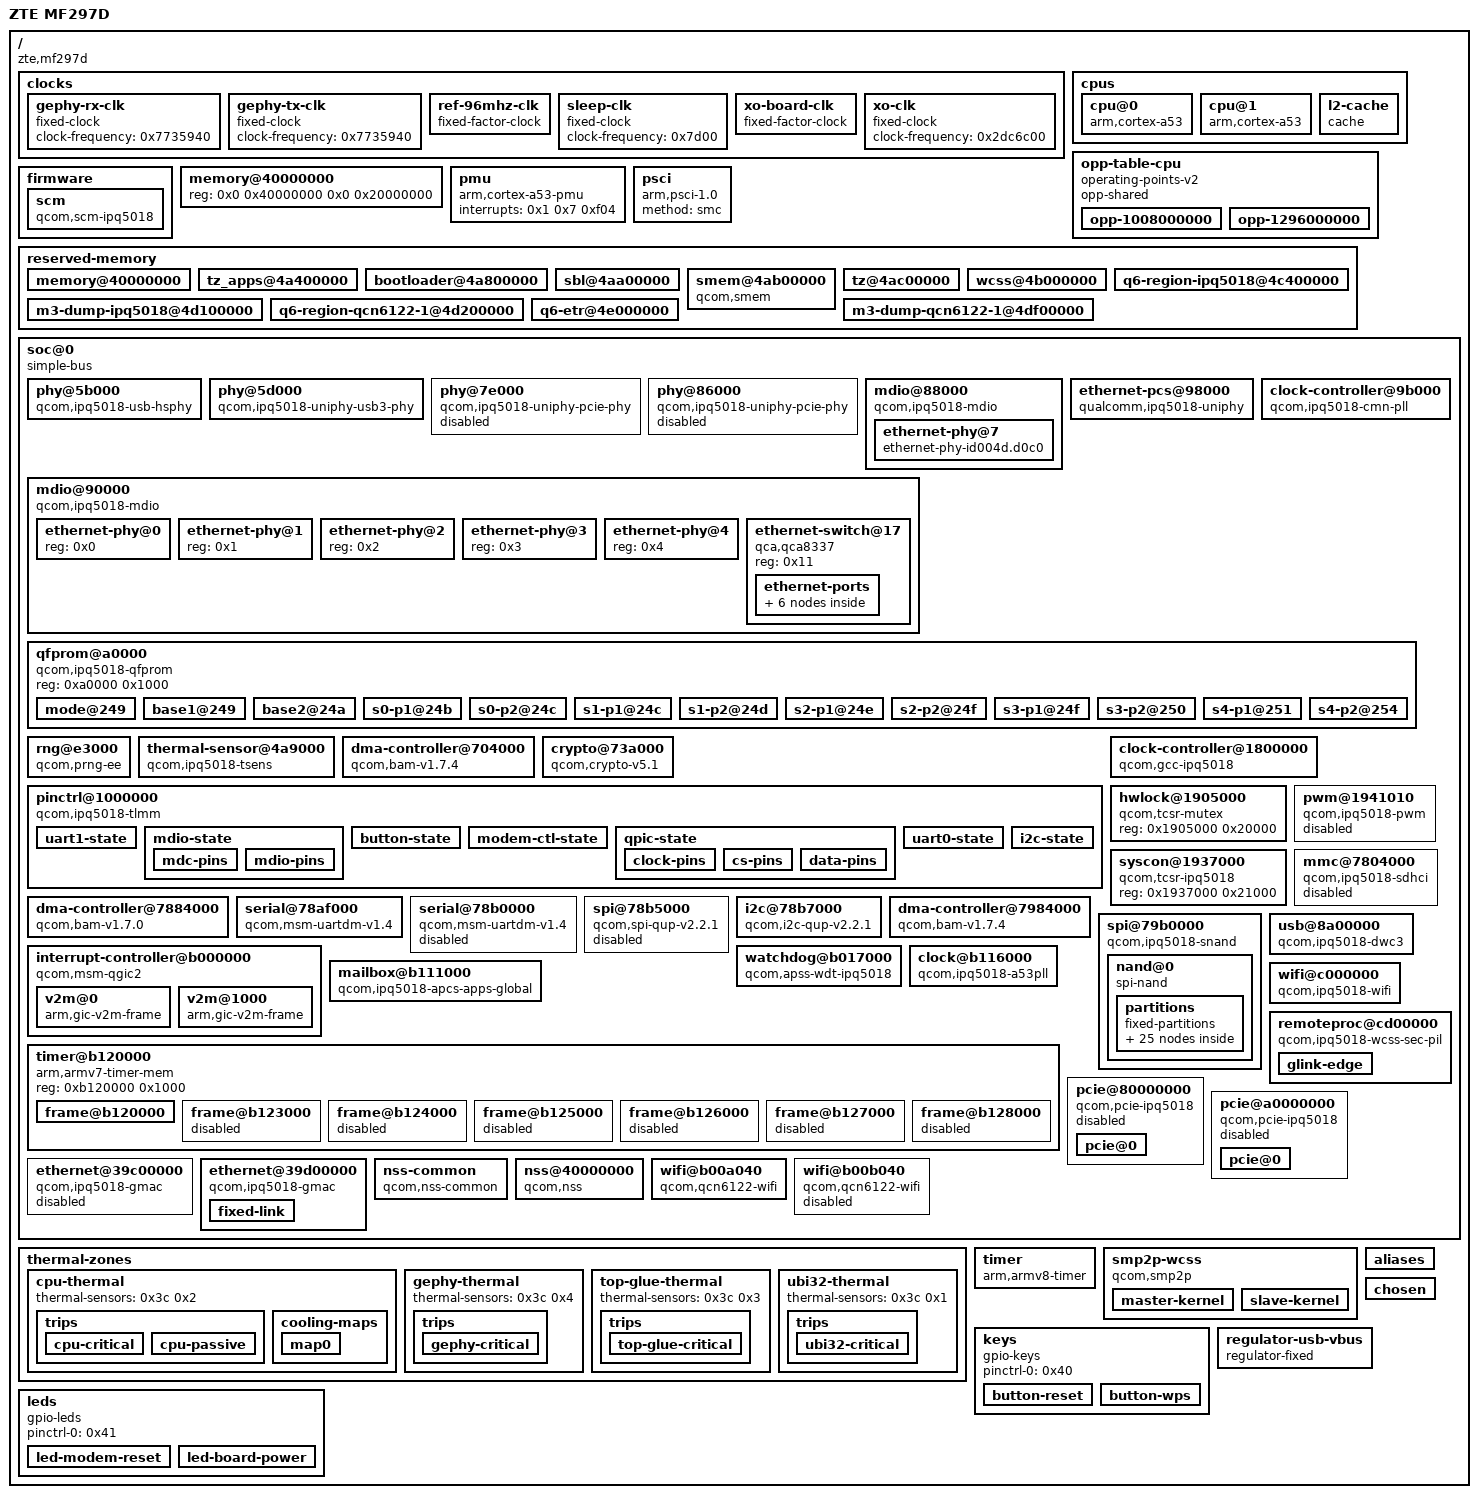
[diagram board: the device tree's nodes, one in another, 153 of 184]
/dts-v1/;

/ {
    interrupt-parent = <0x1>;
    #address-cells = <0x2>;
    #size-cells = <0x2>;
    model = "ZTE MF297D";
    compatible = "zte,mf297d", "qcom,ipq5018";
    clocks {
        gephy-rx-clk {
            compatible = "fixed-clock";
            clock-frequency = <0x7735940>;
            #clock-cells = <0x0>;
            phandle = <0x27>;
        };
        gephy-tx-clk {
            compatible = "fixed-clock";
            clock-frequency = <0x7735940>;
            #clock-cells = <0x0>;
            phandle = <0x28>;
        };
        ref-96mhz-clk {
            compatible = "fixed-factor-clock";
            clocks = <0x2>;
            #clock-cells = <0x0>;
            clock-div = <0x1>;
            clock-mult = <0x2>;
            phandle = <0x3>;
        };
        sleep-clk {
            compatible = "fixed-clock";
            #clock-cells = <0x0>;
            clock-frequency = <0x7d00>;
            phandle = <0x23>;
        };
        xo-board-clk {
            compatible = "fixed-factor-clock";
            clocks = <0x3>;
            #clock-cells = <0x0>;
            clock-div = <0x4>;
            clock-mult = <0x1>;
            phandle = <0x22>;
        };
        xo-clk {
            compatible = "fixed-clock";
            #clock-cells = <0x0>;
            clock-frequency = <0x2dc6c00>;
            phandle = <0x2>;
        };
    };
    cpus {
        #address-cells = <0x1>;
        #size-cells = <0x0>;
        cpu@0 {
            device_type = "cpu";
            compatible = "arm,cortex-a53";
            reg = <0x0>;
            enable-method = "psci";
            next-level-cache = <0x4>;
            clocks = <0x5 0x1>;
            operating-points-v2 = <0x6>;
            #cooling-cells = <0x2>;
            phandle = <0x3e>;
        };
        cpu@1 {
            device_type = "cpu";
            compatible = "arm,cortex-a53";
            reg = <0x1>;
            enable-method = "psci";
            next-level-cache = <0x4>;
            clocks = <0x5 0x1>;
            operating-points-v2 = <0x6>;
            #cooling-cells = <0x2>;
            phandle = <0x3f>;
        };
        l2-cache {
            compatible = "cache";
            cache-level = <0x2>;
            cache-size = <0x80000>;
            cache-unified;
            phandle = <0x4>;
        };
    };
    opp-table-cpu {
        compatible = "operating-points-v2";
        opp-shared;
        phandle = <0x6>;
        opp-1008000000 {
            opp-hz = <0x0 0x3c14dc00>;
            opp-microvolt = <0x10c8e0>;
            clock-latency-ns = <0x30d40>;
        };
        opp-1296000000 {
            opp-hz = <0x0 0x4d3f6400>;
            opp-microvolt = <0x10c8e0>;
            clock-latency-ns = <0x30d40>;
        };
    };
    firmware {
        scm {
            compatible = "qcom,scm-ipq5018", "qcom,scm";
            qcom,dload-mode = <0x7 0x6100>;
            qcom,sdi-enabled;
        };
    };
    memory@40000000 {
        device_type = "memory";
        reg = <0x0 0x40000000 0x0 0x20000000>;
    };
    pmu {
        compatible = "arm,cortex-a53-pmu";
        interrupts = <0x1 0x7 0xf04>;
    };
    psci {
        compatible = "arm,psci-1.0";
        method = "smc";
    };
    reserved-memory {
        #address-cells = <0x2>;
        #size-cells = <0x2>;
        ranges;
        memory@40000000 {
            reg = <0x0 0x40000000 0x0 0x1000000>;
            no-map;
            phandle = <0x39>;
        };
        tz_apps@4a400000 {
            reg = <0x0 0x4a400000 0x0 0x400000>;
            no-map;
        };
        bootloader@4a800000 {
            reg = <0x0 0x4a800000 0x0 0x200000>;
            no-map;
        };
        sbl@4aa00000 {
            reg = <0x0 0x4aa00000 0x0 0x100000>;
            no-map;
        };
        smem@4ab00000 {
            compatible = "qcom,smem";
            reg = <0x0 0x4ab00000 0x0 0x100000>;
            no-map;
            hwlocks = <0x8 0x3>;
        };
        tz@4ac00000 {
            reg = <0x0 0x4ac00000 0x0 0x400000>;
            no-map;
        };
        wcss@4b000000 {
            reg = <0x0 0x4b000000 0x0 0x1400000>;
            no-map;
            phandle = <0x36>;
        };
        q6-region-ipq5018@4c400000 {
            reg = <0x0 0x4c400000 0x0 0xd00000>;
            no-map;
            phandle = <0x33>;
        };
        m3-dump-ipq5018@4d100000 {
            reg = <0x0 0x4d100000 0x0 0x100000>;
            no-map;
            phandle = <0x34>;
        };
        q6-region-qcn6122-1@4d200000 {
            reg = <0x0 0x4d200000 0x0 0xd00000>;
            no-map;
            phandle = <0x3a>;
        };
        m3-dump-qcn6122-1@4df00000 {
            reg = <0x0 0x4df00000 0x0 0x100000>;
            no-map;
            phandle = <0x3b>;
        };
        q6-etr@4e000000 {
            reg = <0x0 0x4e000000 0x0 0x500000>;
            no-map;
        };
    };
    soc@0 {
        compatible = "simple-bus";
        #address-cells = <0x1>;
        #size-cells = <0x1>;
        ranges = <0x0 0x0 0x0 0xffffffff>;
        phy@5b000 {
            compatible = "qcom,ipq5018-usb-hsphy";
            reg = <0x5b000 0x120>;
            clocks = <0x9 0x77>;
            resets = <0x9 0x4f>;
            #phy-cells = <0x0>;
            status = "okay";
            vdd-supply = <0xa>;
            phandle = <0x2f>;
        };
        phy@5d000 {
            compatible = "qcom,ipq5018-uniphy-usb3-phy";
            reg = <0x5d000 0x800>;
            clocks = <0x9 0x77 0x9 0xa9>;
            resets = <0x9 0x63>;
            #clock-cells = <0x0>;
            #phy-cells = <0x0>;
            qcom,phy-usb-mux-sel = <0x7 0x10540>;
            status = "okay";
            vdd-supply = <0xa>;
            phandle = <0x26>;
        };
        phy@7e000 {
            compatible = "qcom,ipq5018-uniphy-pcie-phy";
            reg = <0x7e000 0x800>;
            clocks = <0x9 0x42>;
            resets = <0x9 0x2f 0x9 0x30>;
            #clock-cells = <0x0>;
            #phy-cells = <0x0>;
            num-lanes = <0x1>;
            status = "disabled";
            phandle = <0x25>;
        };
        phy@86000 {
            compatible = "qcom,ipq5018-uniphy-pcie-phy";
            reg = <0x86000 0x1000>;
            clocks = <0x9 0x3c>;
            resets = <0x9 0x23 0x9 0x24>;
            #clock-cells = <0x0>;
            #phy-cells = <0x0>;
            num-lanes = <0x2>;
            status = "disabled";
            phandle = <0x24>;
        };
        mdio@88000 {
            compatible = "qcom,ipq5018-mdio", "qcom,ipq40xx-mdio";
            reg = <0x88000 0x64 0x19475c4 0x4>;
            #address-cells = <0x1>;
            #size-cells = <0x0>;
            clocks = <0x9 0x35>;
            clock-names = "gcc_mdio_ahb_clk";
            status = "okay";
            ethernet-phy@7 {
                compatible = "ethernet-phy-id004d.d0c0";
                reg = <0x7>;
                clocks = <0x9 0x24 0x9 0x25>;
                clock-names = "rx", "tx";
                resets = <0x9 0x6f>;
                phandle = <0x38>;
            };
        };
        mdio@90000 {
            compatible = "qcom,ipq5018-mdio";
            reg = <0x90000 0x64>;
            #address-cells = <0x1>;
            #size-cells = <0x0>;
            clocks = <0x9 0x36>;
            clock-names = "gcc_mdio_ahb_clk";
            status = "okay";
            pinctrl-0 = <0xb>;
            pinctrl-names = "default";
            ethernet-phy@0 {
                reg = <0x0>;
            };
            ethernet-phy@1 {
                reg = <0x1>;
                phandle = <0xc>;
            };
            ethernet-phy@2 {
                reg = <0x2>;
                phandle = <0xd>;
            };
            ethernet-phy@3 {
                reg = <0x3>;
                phandle = <0xe>;
            };
            ethernet-phy@4 {
                reg = <0x4>;
                phandle = <0xf>;
            };
            ethernet-switch@17 {
                compatible = "qca,qca8337";
                reg = <0x11>;
                #address-cells = <0x1>;
                #size-cells = <0x0>;
                ethernet-ports {
                    #address-cells = <0x1>;
                    #size-cells = <0x0>;
                    ethernet-port@2 {
                        reg = <0x2>;
                        label = "lan3";
                        phy-handle = <0xc>;
                    };
                    ethernet-port@3 {
                        reg = <0x3>;
                        label = "lan2";
                        phy-handle = <0xd>;
                    };
                    ethernet-port@4 {
                        reg = <0x4>;
                        label = "lan1";
                        phy-handle = <0xe>;
                    };
                    ethernet-port@5 {
                        reg = <0x5>;
                        label = "lan4";
                        phy-handle = <0xf>;
                    };
                    ethernet-port@6 {
                        reg = <0x6>;
                        label = "cpu";
                        phy-mode = "sgmii";
                        ethernet = <0x10>;
                        qca,sgmii-enable-pll;
                        fixed-link {
                            speed = <0x3e8>;
                            full-duplex;
                        };
                    };
                };
            };
        };
        ethernet-pcs@98000 {
            compatible = "qualcomm,ipq5018-uniphy";
            reg = <0x98000 0x800>;
            #clock-cells = <0x1>;
            clocks = <0x9 0x6e 0x9 0x70 0x9 0x6f 0x9 0x71 0x11 0x3>;
            clock-names = "ahb", "sys", "port5_rx", "port5_tx", "ref";
            clock-output-names = "uniphy0_gcc_rx_clk", "uniphy0_gcc_tx_clk", "uniphy0_ref_clk";
            resets = <0x9 0x6e>;
            reset-names = "soft";
            #pcs-cells = <0x0>;
            status = "okay";
            assigned-clocks = <0x12 0x2>;
            assigned-clock-rates = <0x17d7840>;
            phandle = <0x12>;
        };
        clock-controller@9b000 {
            compatible = "qcom,ipq5018-cmn-pll";
            reg = <0x9b000 0x800>;
            clocks = <0x3 0x9 0x1d 0x9 0x1e>;
            clock-names = "ref", "ahb", "sys";
            #clock-cells = <0x1>;
            assigned-clocks = <0x11 0x0>;
            assigned-clock-rates-u64 = <0x1 0x1e1a3000>;
            phandle = <0x11>;
        };
        qfprom@a0000 {
            compatible = "qcom,ipq5018-qfprom", "qcom,qfprom";
            reg = <0xa0000 0x1000>;
            #address-cells = <0x1>;
            #size-cells = <0x1>;
            status = "okay";
            mode@249 {
                reg = <0x249 0x1>;
                bits = <0x0 0x3>;
                phandle = <0x13>;
            };
            base1@249 {
                reg = <0x249 0x2>;
                bits = <0x3 0x8>;
                phandle = <0x14>;
            };
            base2@24a {
                reg = <0x24a 0x2>;
                bits = <0x3 0x8>;
                phandle = <0x15>;
            };
            s0-p1@24b {
                reg = <0x24b 0x2>;
                bits = <0x2 0x6>;
                phandle = <0x16>;
            };
            s0-p2@24c {
                reg = <0x24c 0x1>;
                bits = <0x1 0x6>;
                phandle = <0x17>;
            };
            s1-p1@24c {
                reg = <0x24c 0x2>;
                bits = <0x7 0x6>;
                phandle = <0x18>;
            };
            s1-p2@24d {
                reg = <0x24d 0x2>;
                bits = <0x5 0x6>;
                phandle = <0x19>;
            };
            s2-p1@24e {
                reg = <0x24e 0x2>;
                bits = <0x3 0x6>;
                phandle = <0x1a>;
            };
            s2-p2@24f {
                reg = <0x24f 0x1>;
                bits = <0x1 0x6>;
                phandle = <0x1b>;
            };
            s3-p1@24f {
                reg = <0x24f 0x2>;
                bits = <0x7 0x6>;
                phandle = <0x1c>;
            };
            s3-p2@250 {
                reg = <0x250 0x2>;
                bits = <0x5 0x6>;
                phandle = <0x1d>;
            };
            s4-p1@251 {
                reg = <0x251 0x2>;
                bits = <0x3 0x6>;
                phandle = <0x1e>;
            };
            s4-p2@254 {
                reg = <0x254 0x1>;
                bits = <0x0 0x6>;
                phandle = <0x1f>;
            };
        };
        rng@e3000 {
            compatible = "qcom,prng-ee";
            reg = <0xe3000 0x1000>;
            clocks = <0x9 0x43>;
            clock-names = "core";
            status = "okay";
        };
        thermal-sensor@4a9000 {
            compatible = "qcom,ipq5018-tsens";
            reg = <0x4a9000 0x1000 0x4a8000 0x1000>;
            nvmem-cells = <0x13 0x14 0x15 0x16 0x17 0x18 0x19 0x1a 0x1b 0x1c 0x1d 0x1e 0x1f>;
            nvmem-cell-names = "mode", "base1", "base2", "s0_p1", "s0_p2", "s1_p1", "s1_p2", "s2_p1", "s2_p2", "s3_p1", "s3_p2", "s4_p1", "s4_p2";
            interrupts = <0x0 0xb8 0x1>;
            interrupt-names = "uplow";
            #qcom,sensors = <0x5>;
            #thermal-sensor-cells = <0x1>;
            phandle = <0x3c>;
        };
        dma-controller@704000 {
            compatible = "qcom,bam-v1.7.4", "qcom,bam-v1.7.0";
            reg = <0x704000 0x20000>;
            interrupts = <0x0 0xcf 0x4>;
            clocks = <0x9 0x1f>;
            clock-names = "bam_clk";
            #dma-cells = <0x1>;
            qcom,ee = <0x1>;
            qcom,controlled-remotely;
            status = "okay";
            phandle = <0x20>;
        };
        crypto@73a000 {
            compatible = "qcom,crypto-v5.1";
            reg = <0x73a000 0x6000>;
            clocks = <0x9 0x1f 0x9 0x20 0x9 0x21>;
            clock-names = "iface", "bus", "core";
            dmas = <0x20 0x2 0x20 0x3>;
            dma-names = "rx", "tx";
            status = "okay";
        };
        pinctrl@1000000 {
            compatible = "qcom,ipq5018-tlmm";
            reg = <0x1000000 0x300000>;
            interrupts = <0x0 0xd0 0x4>;
            gpio-controller;
            #gpio-cells = <0x2>;
            gpio-ranges = <0x21 0x0 0x0 0x2f>;
            interrupt-controller;
            #interrupt-cells = <0x2>;
            phandle = <0x21>;
            uart1-state {
                pins = "gpio31", "gpio32", "gpio33", "gpio34";
                function = "blsp1_uart1";
                drive-strength = <0x8>;
                bias-pull-down;
            };
            mdio-state {
                phandle = <0xb>;
                mdc-pins {
                    pins = "gpio36";
                    function = "mdc";
                    drive-strength = <0x8>;
                    bias-pull-up;
                };
                mdio-pins {
                    pins = "gpio37";
                    function = "mdio";
                    drive-strength = <0x8>;
                    bias-pull-up;
                };
            };
            button-state {
                pins = "gpio32", "gpio38";
                function = "gpio";
                drive-strength = <0x8>;
                bias-pull-up;
                phandle = <0x40>;
            };
            modem-ctl-state {
                pins = "gpio26", "gpio35";
                function = "gpio";
                drive-strength = <0x8>;
                bias-disable;
                phandle = <0x41>;
            };
            qpic-state {
                phandle = <0x2d>;
                clock-pins {
                    pins = "gpio9";
                    function = "qspi_clk";
                    drive-strength = <0x8>;
                    bias-disable;
                };
                cs-pins {
                    pins = "gpio8";
                    function = "qspi_cs";
                    drive-strength = <0x8>;
                    bias-disable;
                };
                data-pins {
                    pins = "gpio4", "gpio5", "gpio6", "gpio7";
                    function = "qspi_data";
                    drive-strength = <0x8>;
                    bias-disable;
                };
            };
            uart0-state {
                pins = "gpio20", "gpio21";
                function = "blsp0_uart0";
                drive-strength = <0x8>;
                bias-disable;
                phandle = <0x29>;
            };
            i2c-state {
                pins = "gpio33", "gpio34";
                function = "blsp2_i2c0";
                drive-strength = <0x8>;
                bias-disable;
                phandle = <0x2b>;
            };
        };
        clock-controller@1800000 {
            compatible = "qcom,gcc-ipq5018";
            reg = <0x1800000 0x80000>;
            clocks = <0x22 0x23 0x24 0x25 0x26 0x27 0x28 0x12 0x0 0x12 0x1>;
            #clock-cells = <0x1>;
            #reset-cells = <0x1>;
            phandle = <0x9>;
        };
        hwlock@1905000 {
            compatible = "qcom,tcsr-mutex";
            reg = <0x1905000 0x20000>;
            #hwlock-cells = <0x1>;
            phandle = <0x8>;
        };
        syscon@1937000 {
            compatible = "qcom,tcsr-ipq5018", "syscon";
            reg = <0x1937000 0x21000>;
            phandle = <0x7>;
        };
        pwm@1941010 {
            compatible = "qcom,ipq5018-pwm", "qcom,ipq6018-pwm";
            reg = <0x1941010 0x20>;
            clocks = <0x9 0x12>;
            assigned-clocks = <0x9 0x12>;
            assigned-clock-rates = <0x5f5e100>;
            #pwm-cells = <0x3>;
            status = "disabled";
        };
        mmc@7804000 {
            compatible = "qcom,ipq5018-sdhci", "qcom,sdhci-msm-v5";
            reg = <0x7804000 0x1000>;
            reg-names = "hc";
            interrupts = <0x0 0x7b 0x4 0x0 0x8a 0x4>;
            interrupt-names = "hc_irq", "pwr_irq";
            clocks = <0x9 0x59 0x9 0x5a 0x22>;
            clock-names = "iface", "core", "xo";
            non-removable;
            status = "disabled";
        };
        dma-controller@7884000 {
            compatible = "qcom,bam-v1.7.0";
            reg = <0x7884000 0x1d000>;
            interrupts = <0x0 0xee 0x4>;
            clocks = <0x9 0x13>;
            clock-names = "bam_clk";
            #dma-cells = <0x1>;
            qcom,ee = <0x0>;
            phandle = <0x2a>;
        };
        serial@78af000 {
            compatible = "qcom,msm-uartdm-v1.4", "qcom,msm-uartdm";
            reg = <0x78af000 0x200>;
            interrupts = <0x0 0x6b 0x4>;
            clocks = <0x9 0x1a 0x9 0x13>;
            clock-names = "core", "iface";
            status = "okay";
            pinctrl-0 = <0x29>;
            pinctrl-names = "default";
        };
        serial@78b0000 {
            compatible = "qcom,msm-uartdm-v1.4", "qcom,msm-uartdm";
            reg = <0x78b0000 0x200>;
            interrupts = <0x0 0x6c 0x4>;
            clocks = <0x9 0x1b 0x9 0x13>;
            clock-names = "core", "iface";
            status = "disabled";
        };
        spi@78b5000 {
            compatible = "qcom,spi-qup-v2.2.1";
            #address-cells = <0x1>;
            #size-cells = <0x0>;
            reg = <0x78b5000 0x600>;
            interrupts = <0x0 0x5f 0x4>;
            clocks = <0x9 0x15 0x9 0x13>;
            clock-names = "core", "iface";
            dmas = <0x2a 0x4 0x2a 0x5>;
            dma-names = "tx", "rx";
            status = "disabled";
        };
        i2c@78b7000 {
            compatible = "qcom,i2c-qup-v2.2.1";
            reg = <0x78b7000 0x600>;
            #address-cells = <0x1>;
            #size-cells = <0x0>;
            interrupts = <0x0 0x61 0x4>;
            clocks = <0x9 0x18 0x9 0x13>;
            clock-names = "core", "iface";
            clock-frequency = <0x61a80>;
            dmas = <0x2a 0x9 0x2a 0x8>;
            dma-names = "tx", "rx";
            status = "okay";
            pinctrl-0 = <0x2b>;
            pinctrl-names = "default";
        };
        dma-controller@7984000 {
            compatible = "qcom,bam-v1.7.4", "qcom,bam-v1.7.0";
            reg = <0x7984000 0x1c000>;
            interrupts = <0x0 0x92 0x4>;
            clocks = <0x9 0x56>;
            clock-names = "bam_clk";
            #dma-cells = <0x1>;
            qcom,ee = <0x0>;
            status = "okay";
            phandle = <0x2c>;
        };
        spi@79b0000 {
            compatible = "qcom,ipq5018-snand", "qcom,ipq9574-snand";
            reg = <0x79b0000 0x10000>;
            #address-cells = <0x1>;
            #size-cells = <0x0>;
            clocks = <0x9 0x57 0x9 0x56 0x9 0x58>;
            clock-names = "core", "aon", "iom";
            dmas = <0x2c 0x0 0x2c 0x1 0x2c 0x2>;
            dma-names = "tx", "rx", "cmd";
            status = "okay";
            pinctrl-0 = <0x2d>;
            pinctrl-names = "default";
            phandle = <0x2e>;
            nand@0 {
                compatible = "spi-nand";
                reg = <0x0>;
                nand-ecc-engine = <0x2e>;
                nand-ecc-strength = <0x4>;
                nand-ecc-step-size = <0x200>;
                nand-bus-width = <0x8>;
                partitions {
                    compatible = "fixed-partitions";
                    #address-cells = <0x1>;
                    #size-cells = <0x1>;
                    partition@0 {
                        label = "0:sbl1";
                        reg = <0x0 0x80000>;
                        read-only;
                    };
                    partition@80000 {
                        label = "0:mibib";
                        reg = <0x80000 0x80000>;
                        read-only;
                    };
                    partition@100000 {
                        label = "0:bootconfig";
                        reg = <0x100000 0x40000>;
                        read-only;
                    };
                    partition@140000 {
                        label = "0:bootconfig1";
                        reg = <0x140000 0x40000>;
                        read-only;
                    };
                    partition@180000 {
                        label = "0:qsee";
                        reg = <0x180000 0x100000>;
                        read-only;
                    };
                    partition@280000 {
                        label = "0:qsee_1";
                        reg = <0x280000 0x100000>;
                        read-only;
                    };
                    partition@380000 {
                        label = "0:devcfg";
                        reg = <0x380000 0x40000>;
                        read-only;
                    };
                    partition@3c0000 {
                        label = "0:devcfg_1";
                        reg = <0x3c0000 0x40000>;
                        read-only;
                    };
                    partition@400000 {
                        label = "0:cdt";
                        reg = <0x400000 0x40000>;
                        read-only;
                    };
                    partition@440000 {
                        label = "0:cdt_1";
                        reg = <0x440000 0x40000>;
                        read-only;
                    };
                    partition@480000 {
                        label = "0:appsblenv";
                        reg = <0x480000 0x80000>;
                    };
                    partition@500000 {
                        label = "0:appsbl";
                        reg = <0x500000 0x140000>;
                        read-only;
                    };
                    partition@640000 {
                        label = "0:appsbl_1";
                        reg = <0x640000 0x140000>;
                        read-only;
                    };
                    partition@780000 {
                        label = "0:art";
                        reg = <0x780000 0x100000>;
                        read-only;
                    };
                    partition@880000 {
                        label = "0:training";
                        reg = <0x880000 0x80000>;
                        read-only;
                    };
                    partition@900000 {
                        label = "fota-flag";
                        reg = <0x900000 0xa0000>;
                        read-only;
                    };
                    partition@9a0000 {
                        label = "mac";
                        reg = <0x9a0000 0x80000>;
                        read-only;
                        nvmem-layout {
                            compatible = "fixed-layout";
                            #address-cells = <0x1>;
                            #size-cells = <0x1>;
                            macaddr@0 {
                                compatible = "mac-base";
                                reg = <0x0 0x6>;
                                #nvmem-cell-cells = <0x1>;
                            };
                        };
                    };
                    partition@a20000 {
                        label = "cfg-param";
                        reg = <0xa20000 0x1400000>;
                        read-only;
                    };
                    partition@1e20000 {
                        label = "log";
                        reg = <0x1e20000 0x600000>;
                        read-only;
                    };
                    partition@2420000 {
                        label = "oops";
                        reg = <0x2420000 0xa0000>;
                    };
                    partition@24c0000 {
                        label = "web";
                        reg = <0x24c0000 0x800000>;
                        read-only;
                    };
                    partition@2cc0000 {
                        label = "rootfs";
                        reg = <0x2cc0000 0x3a00000>;
                    };
                    partition@66c0000 {
                        label = "ubi_data";
                        reg = <0x66c0000 0x9940000>;
                    };
                };
            };
        };
        usb@8a00000 {
            compatible = "qcom,ipq5018-dwc3", "qcom,snps-dwc3";
            reg = <0x8a00000 0xfc100>;
            clocks = <0x9 0x75 0x9 0x66 0x9 0x78 0x9 0x76 0x9 0x72 0x9 0x74>;
            clock-names = "core", "iface", "sleep", "mock_utmi", "aux", "lfps";
            assigned-clocks = <0x9 0x76>;
            assigned-clock-rates = <0x3938700>;
            interrupts = <0x0 0x8c 0x4 0x0 0x86 0x4 0x0 0x79 0x4 0x0 0x78 0x4>;
            interrupt-names = "dwc_usb3", "pwr_event", "dp_hs_phy_irq", "dm_hs_phy_irq";
            resets = <0x9 0x62>;
            phys = <0x2f 0x26>;
            phy-names = "usb2-phy", "usb3-phy";
            tx-fifo-resize;
            snps,is-utmi-l1-suspend;
            snps,hird-threshold = [00];
            snps,dis_u2_susphy_quirk;
            snps,dis_u3_susphy_quirk;
            status = "okay";
            dr_mode = "host";
        };
        interrupt-controller@b000000 {
            compatible = "qcom,msm-qgic2";
            reg = <0xb000000 0x1000 0xb002000 0x2000 0xb001000 0x1000 0xb004000 0x2000>;
            interrupts = <0x1 0x9 0xf04>;
            interrupt-controller;
            #interrupt-cells = <0x3>;
            #address-cells = <0x1>;
            #size-cells = <0x1>;
            ranges = <0x0 0xb00a000 0x1ffa>;
            phandle = <0x1>;
            v2m@0 {
                compatible = "arm,gic-v2m-frame";
                reg = <0x0 0xff8>;
                msi-controller;
                phandle = <0x37>;
            };
            v2m@1000 {
                compatible = "arm,gic-v2m-frame";
                reg = <0x1000 0xff8>;
                msi-controller;
            };
        };
        watchdog@b017000 {
            compatible = "qcom,apss-wdt-ipq5018", "qcom,kpss-wdt";
            reg = <0xb017000 0x40>;
            interrupts = <0x0 0x3 0x1>;
            clocks = <0x23>;
        };
        mailbox@b111000 {
            compatible = "qcom,ipq5018-apcs-apps-global", "qcom,ipq6018-apcs-apps-global";
            reg = <0xb111000 0x1000>;
            #clock-cells = <0x1>;
            clocks = <0x30 0x22 0x9 0x1>;
            clock-names = "pll", "xo", "gpll0";
            #mbox-cells = <0x1>;
            phandle = <0x5>;
        };
        clock@b116000 {
            compatible = "qcom,ipq5018-a53pll";
            reg = <0xb116000 0x40>;
            #clock-cells = <0x0>;
            clocks = <0x22>;
            clock-names = "xo";
            phandle = <0x30>;
        };
        timer@b120000 {
            compatible = "arm,armv7-timer-mem";
            reg = <0xb120000 0x1000>;
            #address-cells = <0x1>;
            #size-cells = <0x1>;
            ranges;
            frame@b120000 {
                reg = <0xb121000 0x1000 0xb122000 0x1000>;
                interrupts = <0x0 0x8 0x4 0x0 0x7 0x4>;
                frame-number = <0x0>;
            };
            frame@b123000 {
                reg = <0xb123000 0x1000>;
                interrupts = <0x0 0x9 0x4>;
                frame-number = <0x1>;
                status = "disabled";
            };
            frame@b124000 {
                frame-number = <0x2>;
                interrupts = <0x0 0xa 0x4>;
                reg = <0xb124000 0x1000>;
                status = "disabled";
            };
            frame@b125000 {
                reg = <0xb125000 0x1000>;
                interrupts = <0x0 0xb 0x4>;
                frame-number = <0x3>;
                status = "disabled";
            };
            frame@b126000 {
                reg = <0xb126000 0x1000>;
                interrupts = <0x0 0xc 0x4>;
                frame-number = <0x4>;
                status = "disabled";
            };
            frame@b127000 {
                reg = <0xb127000 0x1000>;
                interrupts = <0x0 0xd 0x4>;
                frame-number = <0x5>;
                status = "disabled";
            };
            frame@b128000 {
                reg = <0xb128000 0x1000>;
                interrupts = <0x0 0xe 0x4>;
                frame-number = <0x6>;
                status = "disabled";
            };
        };
        wifi@c000000 {
            compatible = "qcom,ipq5018-wifi";
            reg = <0xc000000 0x1000000>;
            interrupt-names = "misc-pulse1", "misc-latch", "sw-exception", "watchdog", "ce0", "ce1", "ce2", "ce3", "ce4", "ce5", "ce6", "ce7", "ce8", "ce9", "ce10", "ce11", "host2wbm-desc-feed", "host2reo-re-injection", "host2reo-command", "host2rxdma-monitor-ring3", "host2rxdma-monitor-ring2", "host2rxdma-monitor-ring1", "reo2ost-exception", "wbm2host-rx-release", "reo2host-status", "reo2host-destination-ring4", "reo2host-destination-ring3", "reo2host-destination-ring2", "reo2host-destination-ring1", "rxdma2host-monitor-destination-mac3", "rxdma2host-monitor-destination-mac2", "rxdma2host-monitor-destination-mac1", "ppdu-end-interrupts-mac3", "ppdu-end-interrupts-mac2", "ppdu-end-interrupts-mac1", "rxdma2host-monitor-status-ring-mac3", "rxdma2host-monitor-status-ring-mac2", "rxdma2host-monitor-status-ring-mac1", "host2rxdma-host-buf-ring-mac3", "host2rxdma-host-buf-ring-mac2", "host2rxdma-host-buf-ring-mac1", "rxdma2host-destination-ring-mac3", "rxdma2host-destination-ring-mac2", "rxdma2host-destination-ring-mac1", "host2tcl-input-ring4", "host2tcl-input-ring3", "host2tcl-input-ring2", "host2tcl-input-ring1", "wbm2host-tx-completions-ring3", "wbm2host-tx-completions-ring2", "wbm2host-tx-completions-ring1", "tcl2host-status-ring", "fatal", "ready", "spawn", "stop-ack";
            status = "okay";
            nss-radio-priority = <0x0>;
            interrupts-extended = <0x1 0x0 0x120 0x1 0x1 0x0 0x121 0x1 0x1 0x0 0x122 0x1 0x1 0x0 0x123 0x1 0x1 0x0 0x124 0x1 0x1 0x0 0x125 0x1 0x1 0x0 0x126 0x1 0x1 0x0 0x127 0x1 0x1 0x0 0x128 0x1 0x1 0x0 0x129 0x1 0x1 0x0 0x12a 0x1 0x1 0x0 0x12b 0x1 0x1 0x0 0x12c 0x1 0x1 0x0 0x12d 0x1 0x1 0x0 0x12e 0x1 0x1 0x0 0x12f 0x1 0x1 0x0 0x130 0x1 0x1 0x0 0x131 0x1 0x1 0x0 0x132 0x1 0x1 0x0 0x133 0x1 0x1 0x0 0x134 0x1 0x1 0x0 0x135 0x1 0x1 0x0 0x136 0x1 0x1 0x0 0x137 0x1 0x1 0x0 0x14e 0x1 0x1 0x0 0x139 0x1 0x1 0x0 0x13a 0x1 0x1 0x0 0x13b 0x1 0x1 0x0 0x13c 0x1 0x1 0x0 0x13d 0x1 0x1 0x0 0x13e 0x1 0x1 0x0 0x13f 0x1 0x1 0x0 0x140 0x1 0x1 0x0 0x141 0x1 0x1 0x0 0x142 0x1 0x1 0x0 0x143 0x1 0x1 0x0 0x144 0x1 0x1 0x0 0x145 0x1 0x1 0x0 0x146 0x1 0x1 0x0 0x147 0x1 0x1 0x0 0x148 0x1 0x1 0x0 0x149 0x1 0x1 0x0 0x14a 0x1 0x1 0x0 0x14b 0x1 0x1 0x0 0x14c 0x1 0x1 0x0 0x14d 0x1 0x1 0x0 0x138 0x1 0x1 0x0 0x14f 0x1 0x1 0x0 0x150 0x1 0x1 0x0 0x151 0x1 0x1 0x0 0x152 0x1 0x1 0x0 0x153 0x1 0x31 0x8 0x0 0x31 0x9 0x0 0x31 0xc 0x0 0x31 0xb 0x0>;
            qcom,smem-states = <0x32 0x8 0x32 0x9 0x32 0xa>;
            qcom,smem-state-names = "shutdown", "stop", "spawn";
            memory-region = <0x33 0x33 0x34>;
            memory-region-names = "q6-region", "m3-region", "m3-dump";
            qcom,rproc = <0x35>;
            qcom,ath11k-fw-memory-mode = <0x2>;
        };
        remoteproc@cd00000 {
            compatible = "qcom,ipq5018-wcss-sec-pil";
            reg = <0xcd00000 0x10000>;
            firmware-name = "ath11k/IPQ5018/hw1.0/q6_fw.mbn";
            interrupts-extended = <0x1 0x0 0x123 0x1 0x31 0x0 0x0 0x31 0x1 0x0 0x31 0x2 0x0 0x31 0x3 0x0>;
            interrupt-names = "wdog", "fatal", "ready", "handover", "stop-ack";
            clocks = <0x9 0x5b 0x9 0x67>;
            clock-names = "sleep", "interconnect";
            qcom,smem-states = <0x32 0x0 0x32 0x1>;
            qcom,smem-state-names = "shutdown", "stop";
            memory-region = <0x36>;
            boot-args = <0x1 0x4 0x2 0xf 0x0 0x0>;
            status = "okay";
            phandle = <0x35>;
            glink-edge {
                interrupts = <0x0 0xb3 0x1>;
                label = "rtr";
                qcom,remote-pid = <0x1>;
                mboxes = <0x5 0x8>;
            };
        };
        pcie@80000000 {
            compatible = "qcom,pcie-ipq5018";
            reg = <0x80000000 0xf1d 0x80000f20 0xa8 0x80001000 0x1000 0x78000 0x3000 0x80100000 0x1000 0x7b000 0x1000>;
            reg-names = "dbi", "elbi", "atu", "parf", "config", "mhi";
            device_type = "pci";
            linux,pci-domain = <0x1>;
            bus-range = <0x0 0xff>;
            num-lanes = <0x1>;
            #address-cells = <0x3>;
            #size-cells = <0x2>;
            max-link-speed = <0x2>;
            phys = <0x25>;
            phy-names = "pciephy";
            ranges = <0x1000000 0x0 0x0 0x80200000 0x0 0x100000 0x2000000 0x0 0x80300000 0x80300000 0x0 0x10000000>;
            msi-map = <0x0 0x37 0x0 0xff8>;
            interrupts = <0x0 0x6f 0x4 0x0 0x70 0x4 0x0 0x71 0x4 0x0 0x72 0x4 0x0 0x73 0x4 0x0 0x74 0x4 0x0 0x75 0x4 0x0 0x76 0x4 0x0 0x77 0x4>;
            interrupt-names = "msi0", "msi1", "msi2", "msi3", "msi4", "msi5", "msi6", "msi7", "global";
            #interrupt-cells = <0x1>;
            interrupt-map-mask = <0x0 0x0 0x0 0x7>;
            interrupt-map = <0x0 0x0 0x0 0x1 0x1 0x0 0x0 0x8e 0x4 0x0 0x0 0x0 0x2 0x1 0x0 0x0 0x8f 0x4 0x0 0x0 0x0 0x3 0x1 0x0 0x0 0x90 0x4 0x0 0x0 0x0 0x4 0x1 0x0 0x0 0x91 0x4>;
            clocks = <0x9 0x64 0x9 0x3f 0x9 0x41 0x9 0x3d 0x9 0x3e 0x9 0x40>;
            clock-names = "iface", "axi_m", "axi_s", "ahb", "aux", "axi_bridge";
            resets = <0x9 0x31 0x9 0x32 0x9 0x33 0x9 0x34 0x9 0x35 0x9 0x36 0x9 0x37 0x9 0x38>;
            reset-names = "pipe", "sleep", "sticky", "axi_m", "axi_s", "ahb", "axi_m_sticky", "axi_s_sticky";
            status = "disabled";
            pcie@0 {
                device_type = "pci";
                reg = <0x0 0x0 0x0 0x0 0x0>;
                bus-range = <0x1 0xff>;
                #address-cells = <0x3>;
                #size-cells = <0x2>;
                ranges;
            };
        };
        pcie@a0000000 {
            compatible = "qcom,pcie-ipq5018";
            reg = <0xa0000000 0xf1d 0xa0000f20 0xa8 0xa0001000 0x1000 0x80000 0x3000 0xa0100000 0x1000 0x83000 0x1000>;
            reg-names = "dbi", "elbi", "atu", "parf", "config", "mhi";
            device_type = "pci";
            linux,pci-domain = <0x0>;
            bus-range = <0x0 0xff>;
            num-lanes = <0x2>;
            #address-cells = <0x3>;
            #size-cells = <0x2>;
            max-link-speed = <0x2>;
            phys = <0x24>;
            phy-names = "pciephy";
            ranges = <0x1000000 0x0 0x0 0xa0200000 0x0 0x100000 0x2000000 0x0 0xa0300000 0xa0300000 0x0 0x10000000>;
            msi-map = <0x0 0x37 0x0 0xff8>;
            interrupts = <0x0 0x34 0x4 0x0 0x37 0x4 0x0 0x38 0x4 0x0 0x39 0x4 0x0 0x3b 0x4 0x0 0x3f 0x4 0x0 0x44 0x4 0x0 0x48 0x4 0x0 0x33 0x4>;
            interrupt-names = "msi0", "msi1", "msi2", "msi3", "msi4", "msi5", "msi6", "msi7", "global";
            #interrupt-cells = <0x1>;
            interrupt-map-mask = <0x0 0x0 0x0 0x7>;
            interrupt-map = <0x0 0x0 0x0 0x1 0x1 0x0 0x0 0x4b 0x4 0x0 0x0 0x0 0x2 0x1 0x0 0x0 0x4e 0x4 0x0 0x0 0x0 0x3 0x1 0x0 0x0 0x4f 0x4 0x0 0x0 0x0 0x4 0x1 0x0 0x0 0x53 0x4>;
            clocks = <0x9 0x63 0x9 0x39 0x9 0x3b 0x9 0x37 0x9 0x38 0x9 0x3a>;
            clock-names = "iface", "axi_m", "axi_s", "ahb", "aux", "axi_bridge";
            resets = <0x9 0x25 0x9 0x26 0x9 0x27 0x9 0x28 0x9 0x29 0x9 0x2a 0x9 0x2b 0x9 0x2c>;
            reset-names = "pipe", "sleep", "sticky", "axi_m", "axi_s", "ahb", "axi_m_sticky", "axi_s_sticky";
            status = "disabled";
            pcie@0 {
                device_type = "pci";
                reg = <0x0 0x0 0x0 0x0 0x0>;
                bus-range = <0x1 0xff>;
                #address-cells = <0x3>;
                #size-cells = <0x2>;
                ranges;
            };
        };
        ethernet@39c00000 {
            compatible = "qcom,ipq5018-gmac", "snps,dwmac";
            reg = <0x39c00000 0x10000>;
            reg-names = "stmmaceth";
            clocks = <0x9 0x29 0x9 0x26 0x9 0x27 0x9 0x5c 0x9 0x5d 0x9 0x28 0x9 0x2a>;
            clock-names = "stmmaceth", "pclk", "ptp_ref", "ahb", "axi", "rx", "tx";
            assigned-clocks = <0x9 0x29 0x9 0x26 0x9 0x27 0x9 0x5c 0x9 0x5d>;
            assigned-clock-rates = <0xe4e1c00 0xe4e1c00 0xe4e1c00 0xe4e1c00 0xe4e1c00>;
            resets = <0x9 0x16>;
            reset-names = "stmmaceth";
            interrupts = <0x0 0x65 0x4>;
            interrupt-names = "macirq";
            phy-handle = <0x38>;
            phy-mode = "sgmii";
            status = "disabled";
        };
        ethernet@39d00000 {
            compatible = "qcom,ipq5018-gmac", "snps,dwmac";
            reg = <0x39d00000 0x10000>;
            reg-names = "stmmaceth";
            clocks = <0x9 0x2e 0x9 0x2b 0x9 0x2c 0x9 0x5e 0x9 0x5f 0x9 0x2d 0x9 0x2f>;
            clock-names = "stmmaceth", "pclk", "ptp_ref", "ahb", "axi", "rx", "tx";
            assigned-clocks = <0x9 0x2e 0x9 0x2b 0x9 0x2c 0x9 0x5e 0x9 0x5f>;
            assigned-clock-rates = <0xe4e1c00 0xe4e1c00 0xe4e1c00 0xe4e1c00 0xe4e1c00>;
            resets = <0x9 0x19>;
            reset-names = "stmmaceth";
            interrupts = <0x0 0x6d 0x4>;
            interrupt-names = "macirq";
            pcs-handle = <0x12>;
            status = "okay";
            phy-mode = "sgmii";
            local-mac-address = [c4 a3 66 2f 2f a6];
            phandle = <0x10>;
            fixed-link {
                speed = <0x3e8>;
                full-duplex;
            };
        };
        nss-common {
            compatible = "qcom,nss-common";
            reg = <0x1868010 0x1>;
            reg-names = "nss-misc-reset";
            memory-region = <0x39>;
        };
        nss@40000000 {
            compatible = "qcom,nss";
            interrupts = <0x0 0x192 0x1 0x0 0x191 0x1 0x0 0x190 0x1 0x0 0x18f 0x1 0x0 0x18e 0x1 0x0 0x18d 0x1 0x0 0x18c 0x1 0x0 0x18b 0x1>;
            reg = <0x7a00000 0x100 0xb111000 0x1000>;
            reg-names = "nphys", "qgic-phys";
            clocks = <0x9 0x69 0x9 0x6b 0x9 0x6a 0x9 0x6d 0x9 0x68 0x9 0x62 0x9 0x6c>;
            clock-names = "nss-cfg-clk", "nss-dbg-clk", "nss-core-clk", "nss-utcm-clk", "nss-axi-clk", "nss-snoc-axi-clk", "nss-nc-axi-clk";
            qcom,id = <0x0>;
            qcom,num-queue = <0x4>;
            qcom,num-irq = <0x8>;
            qcom,num-pri = <0x4>;
            qcom,load-addr = <0x40000000>;
            qcom,low-frequency = <0x32a9f880>;
            qcom,mid-frequency = <0x3b9aca00>;
            qcom,max-frequency = <0x3b9aca00>;
            qcom,ipv4-enabled;
            qcom,ipv4-reasm-enabled;
            qcom,ipv6-enabled;
            qcom,ipv6-reasm-enabled;
            qcom,tun6rd-enabled;
            qcom,l2tpv2-enabled;
            qcom,gre-enabled;
            qcom,map-t-enabled;
            qcom,pppoe-enabled;
            qcom,pptp-enabled;
            qcom,tunipip6-enabled;
            qcom,shaping-enabled;
            qcom,vlan-enabled;
            qcom,vxlan-enabled;
            qcom,match-enabled;
            qcom,mirror-enabled;
            qcom,wlanredirect-enabled;
            qcom,wlan-dataplane-offload-enabled;
            qcom,rmnet_rx-enabled;
        };
        wifi@b00a040 {
            reg = <0xb00a040 0x0>;
            compatible = "qcom,qcn6122-wifi";
            interrupts-extended = <0x1 0x0 0x1a0 0x1 0x1 0x0 0x1a1 0x1 0x1 0x0 0x1a2 0x1 0x1 0x0 0x1a3 0x1 0x1 0x0 0x1a4 0x1 0x1 0x0 0x1a5 0x1 0x1 0x0 0x1a6 0x1 0x1 0x0 0x1a7 0x1 0x1 0x0 0x1a8 0x1 0x1 0x0 0x1a9 0x1 0x1 0x0 0x1aa 0x1 0x1 0x0 0x1ab 0x1 0x1 0x0 0x1ac 0x1 0x31 0x10 0x0 0x31 0x11 0x0 0x31 0x14 0x0 0x31 0x13 0x0>;
            interrupt-names = "ce1", "ce2", "ce3", "ce4", "ce5", "dp1", "dp2", "dp3", "dp4", "dp5", "dp6", "dp7", "dp8", "fatal", "ready", "spawn", "stop-ack";
            qcom,smem-states = <0x32 0x10 0x32 0x11 0x32 0x12>;
            qcom,smem-state-names = "shutdown", "stop", "spawn";
            status = "okay";
            qcom,rproc = <0x35>;
            qcom,ath11k-fw-memory-mode = <0x2>;
            memory-region = <0x3a 0x33 0x3b>;
            memory-region-names = "q6-region", "m3-region", "m3-dump";
        };
        wifi@b00b040 {
            reg = <0xb00b040 0x0>;
            compatible = "qcom,qcn6122-wifi";
            interrupts-extended = <0x1 0x0 0x1c0 0x1 0x1 0x0 0x1c1 0x1 0x1 0x0 0x1c2 0x1 0x1 0x0 0x1c3 0x1 0x1 0x0 0x1c4 0x1 0x1 0x0 0x1c5 0x1 0x1 0x0 0x1c6 0x1 0x1 0x0 0x1c7 0x1 0x1 0x0 0x1c8 0x1 0x1 0x0 0x1c9 0x1 0x1 0x0 0x1ca 0x1 0x1 0x0 0x1cb 0x1 0x1 0x0 0x1cc 0x1 0x31 0x18 0x0 0x31 0x19 0x0 0x31 0x1c 0x0 0x31 0x1b 0x0>;
            interrupt-names = "ce1", "ce2", "ce3", "ce4", "ce5", "dp1", "dp2", "dp3", "dp4", "dp5", "dp6", "dp7", "dp8", "fatal", "ready", "spawn", "stop-ack";
            qcom,smem-states = <0x32 0x18 0x32 0x19 0x32 0x1a>;
            qcom,smem-state-names = "shutdown", "stop", "spawn";
            status = "disabled";
        };
    };
    thermal-zones {
        cpu-thermal {
            thermal-sensors = <0x3c 0x2>;
            trips {
                cpu-critical {
                    temperature = <0x1d4c0>;
                    hysteresis = <0x3e8>;
                    type = "critical";
                };
                cpu-passive {
                    temperature = <0x186a0>;
                    hysteresis = <0x3e8>;
                    type = "passive";
                    phandle = <0x3d>;
                };
            };
            cooling-maps {
                map0 {
                    trip = <0x3d>;
                    cooling-device = <0x3e 0xffffffff 0xffffffff 0x3f 0xffffffff 0xffffffff>;
                };
            };
        };
        gephy-thermal {
            thermal-sensors = <0x3c 0x4>;
            trips {
                gephy-critical {
                    temperature = <0x1d4c0>;
                    hysteresis = <0x3e8>;
                    type = "critical";
                };
            };
        };
        top-glue-thermal {
            thermal-sensors = <0x3c 0x3>;
            trips {
                top-glue-critical {
                    temperature = <0x1d4c0>;
                    hysteresis = <0x3e8>;
                    type = "critical";
                };
            };
        };
        ubi32-thermal {
            thermal-sensors = <0x3c 0x1>;
            trips {
                ubi32-critical {
                    temperature = <0x1d4c0>;
                    hysteresis = <0x3e8>;
                    type = "critical";
                };
            };
        };
    };
    timer {
        compatible = "arm,armv8-timer";
        interrupts = <0x1 0x2 0xf08 0x1 0x3 0xf08 0x1 0x4 0xf08 0x1 0x1 0xf08>;
    };
    smp2p-wcss {
        compatible = "qcom,smp2p";
        qcom,smem = <0x1b3 0x1ac>;
        interrupt-parent = <0x1>;
        interrupts = <0x0 0xb1 0x1>;
        mboxes = <0x5 0x9>;
        qcom,local-pid = <0x0>;
        qcom,remote-pid = <0x1>;
        master-kernel {
            qcom,entry-name = "master-kernel";
            qcom,smp2p-feature-ssr-ack;
            #qcom,smem-state-cells = <0x1>;
            phandle = <0x32>;
        };
        slave-kernel {
            qcom,entry-name = "slave-kernel";
            interrupt-controller;
            #interrupt-cells = <0x2>;
            phandle = <0x31>;
        };
    };
    aliases {
        ethernet1 = "/soc@0/ethernet@39d00000";
        label-mac-device = "/soc@0/ethernet@39d00000";
        serial0 = "/soc@0/serial@78af000";
        i2c0 = "/soc@0/i2c@78b7000";
    };
    chosen {
        bootargs-append = " ubi.mtd=ubi_data root=/dev/ubiblock0_1 swiotlb=1 coherent_pool=2M panic=5";
        stdout-path = "serial0:115200n8";
    };
    keys {
        compatible = "gpio-keys";
        pinctrl-0 = <0x40>;
        pinctrl-names = "default";
        button-reset {
            label = "reset";
            gpios = <0x21 0x20 0x1>;
            linux,code = <0x198>;
            debounce-interval = <0x3c>;
        };
        button-wps {
            label = "wps";
            gpios = <0x21 0x26 0x1>;
            linux,code = <0x211>;
            debounce-interval = <0x3c>;
        };
    };
    leds {
        compatible = "gpio-leds";
        pinctrl-0 = <0x41>;
        pinctrl-names = "default";
        led-modem-reset {
            label = "ctl:modem-reset";
            gpios = <0x21 0x1a 0x0>;
            default-state = "off";
        };
        led-board-power {
            label = "ctl:board-power";
            gpios = <0x21 0x23 0x1>;
            default-state = "on";
        };
    };
    regulator-usb-vbus {
        compatible = "regulator-fixed";
        regulator-name = "usb_vbus";
        regulator-min-microvolt = <0x4c4b40>;
        regulator-max-microvolt = <0x4c4b40>;
        gpio = <0x21 0x18 0x1>;
        regulator-boot-on;
        regulator-always-on;
        phandle = <0xa>;
    };
};
